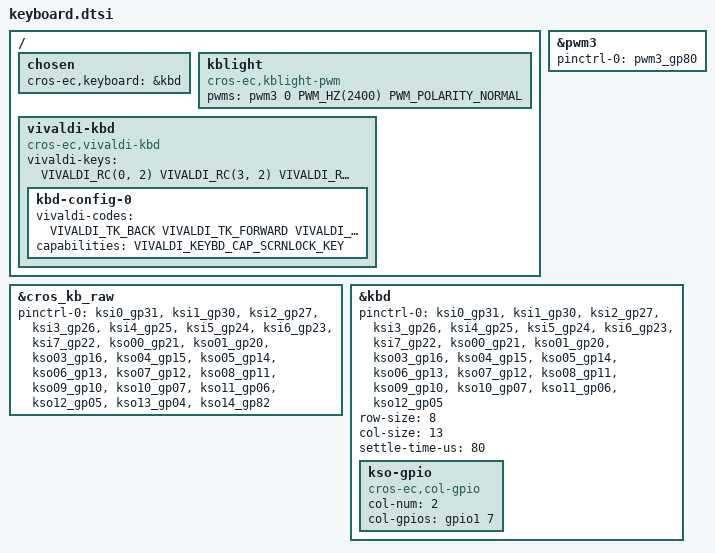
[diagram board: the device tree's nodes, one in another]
/* Copyright 2022 The ChromiumOS Authors
 * Use of this source code is governed by a BSD-style license that can be
 * found in the LICENSE file.
 */

#include <dt-bindings/vivaldi_kbd.h>

/ {
	chosen {
		cros-ec,keyboard = &kbd;
	};

	kblight: kblight {
		compatible = "cros-ec,kblight-pwm";
		pwms = <&pwm3 0 PWM_HZ(2400) PWM_POLARITY_NORMAL>;
	};

	vivaldi-kbd {
		compatible = "cros-ec,vivaldi-kbd";
		vivaldi-keys = <
			VIVALDI_RC(0, 2)   /* T1 */
			VIVALDI_RC(3, 2)   /* T2 */
			VIVALDI_RC(2, 2)   /* T3 */
			VIVALDI_RC(1, 2)   /* T4 */
			VIVALDI_RC(3, 4)   /* T5 */
			VIVALDI_RC(2, 4)   /* T6 */
			VIVALDI_RC(1, 4)   /* T7 */
			VIVALDI_RC(2, 9)   /* T8 */
			VIVALDI_RC(1, 9)   /* T9 */
			VIVALDI_RC(0, 4)   /* T10 */
			VIVALDI_RC(0, 1)   /* T11 */
			VIVALDI_RC(1, 5)   /* T12 */
			VIVALDI_RC(3, 5)   /* T13 */
			VIVALDI_RC(0, 9)   /* T14 */
			VIVALDI_RC(0, 11)  /* T15 */
		>;

		kbd-config-0 {
			vivaldi-codes = <
				VIVALDI_TK_BACK              /* T1 */
				VIVALDI_TK_FORWARD           /* T2 */
				VIVALDI_TK_REFRESH           /* T3 */
				VIVALDI_TK_FULLSCREEN        /* T4 */
				VIVALDI_TK_OVERVIEW          /* T5 */
				VIVALDI_TK_BRIGHTNESS_DOWN   /* T6 */
				VIVALDI_TK_BRIGHTNESS_UP     /* T7 */
				VIVALDI_TK_VOL_MUTE          /* T8 */
				VIVALDI_TK_VOL_DOWN          /* T9 */
				VIVALDI_TK_VOL_UP            /* T10 */
			>;
			capabilities = <VIVALDI_KEYBD_CAP_SCRNLOCK_KEY>;
		};
	};
};

&pwm3 {
	status = "okay";
	pinctrl-0 = <&pwm3_gp80>;
	pinctrl-names = "default";
};

&cros_kb_raw {
	status = "okay";
	/* No KSO2 (it's inverted and implemented by GPIO) */
	pinctrl-0 = <
		&ksi0_gp31
		&ksi1_gp30
		&ksi2_gp27
		&ksi3_gp26
		&ksi4_gp25
		&ksi5_gp24
		&ksi6_gp23
		&ksi7_gp22
		&kso00_gp21
		&kso01_gp20
		&kso03_gp16
		&kso04_gp15
		&kso05_gp14
		&kso06_gp13
		&kso07_gp12
		&kso08_gp11
		&kso09_gp10
		&kso10_gp07
		&kso11_gp06
		&kso12_gp05
		&kso13_gp04
		&kso14_gp82
	>;
	pinctrl-names = "default";
};

&kbd {
	/* Experimental: only used for testing with the upstream keyboard
	 * driver.
	 */
	status = "okay";
	pinctrl-0 = <
		&ksi0_gp31 /* KSI0 PIN31 */
		&ksi1_gp30 /* KSI1 PIN30 */
		&ksi2_gp27 /* KSI2 PIN27 */
		&ksi3_gp26 /* KSI3 PIN26 */
		&ksi4_gp25 /* KSI4 PIN25 */
		&ksi5_gp24 /* KSI5 PIN24 */
		&ksi6_gp23 /* KSI6 PIN23 */
		&ksi7_gp22 /* KSI7 PIN22 */
		&kso00_gp21 /* KSO00 PIN21 */
		&kso01_gp20 /* KSO01 PIN20 */
		&kso03_gp16 /* KSO03 PIN16 */
		&kso04_gp15 /* KSO04 PIN15 */
		&kso05_gp14 /* KSO05 PIN14 */
		&kso06_gp13 /* KSO06 PIN13 */
		&kso07_gp12 /* KSO07 PIN12 */
		&kso08_gp11 /* KSO08 PIN11 */
		&kso09_gp10 /* KSO09 PIN10 */
		&kso10_gp07 /* KSO10 PIN07 */
		&kso11_gp06 /* KSO11 PIN06 */
		&kso12_gp05 /* KSO12 PIN05 */
	>;
	pinctrl-names = "default";
	row-size = <8>;
	col-size = <13>;
	settle-time-us = <80>;

	kso-gpio {
		compatible = "cros-ec,col-gpio";
		col-num = <2>;
		col-gpios = <&gpio1 7 GPIO_ACTIVE_HIGH>;
	};
};
